# SF32LB52x register map
File version: 1.0
CPU: CM33 r0p1, little endian, MPU, FPU, 3 interrupt priority bits
Registers are 32-bit, read-write, reset 0x0 unless marked. A register's access mark holds for its fields unless they carry their own. Offsets are from the block's base; [hi:lo] are bit positions; {n}, {i} and the like mark numbered series.

## HPSYS_AON
Base 0x500C0000
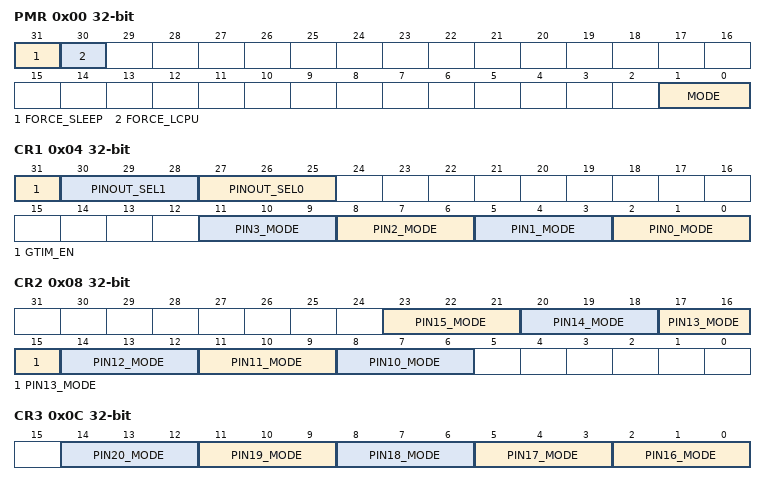
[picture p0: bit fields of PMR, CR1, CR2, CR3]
0x00 PMR — Power Mode Register
  [31] FORCE_SLEEP — Set 1 to force enter low power mode. Will be cleared automatically
  [30] FORCE_LCPU — for debug only
  [1:0] MODE — Power Mode: 2'h0 - active; 2'h1 - light sleep; 2'h2 - deep sleep; 2'h3 - standby
0x04 CR1 — Control Register 1
  [31] GTIM_EN — Enable global timer
  [30:28] PINOUT_SEL1 — for debug only
  [27:25] PINOUT_SEL0 — for debug only
  [11:9] PIN3_MODE — mode for wakeup PIN3 (PA27)
  [8:6] PIN2_MODE — mode for wakeup PIN2 (PA26)
  [5:3] PIN1_MODE — mode for wakeup PIN1 (PA25)
  [2:0] PIN0_MODE — mode for wakeup PIN0 (PA24) 0 - high level, 1 - low level, 2 - pos edge, 3 - neg edge, 4/5/6/7: pos or neg edge
0x08 CR2 — Control Register 2
  [3n-22:3n-24] PIN{n}_MODE (n=11..15) — mode for wakeup PIN{n} (PA{n+24})
  [8:6] PIN10_MODE — mode for wakeup PIN10 (PA34) 0 - high level, 1 - low level, 2 - pos edge, 3 - neg edge, 4/5/6/7: pos or neg edge
0x0C CR3 — Control Register 3
  [3n-46:3n-48] PIN{n}_MODE (n=17..20) — mode for wakeup PIN{n} (PA{n+24})
  [2:0] PIN16_MODE — mode for wakeup PIN16 (PA40) 0 - high level, 1 - low level, 2 - pos edge, 3 - neg edge, 4/5/6/7: pos or neg edge
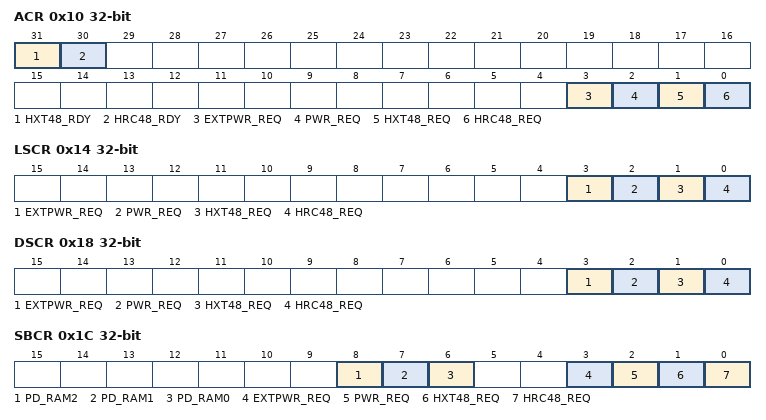
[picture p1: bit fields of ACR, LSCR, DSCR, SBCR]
0x10 ACR — Active Mode Control register
  [31] HXT48_RDY — Indicate hxt48 is ready
  [30] HRC48_RDY — Indicate hrc48 is ready
  [3] EXTPWR_REQ — for debug only
  [2] PWR_REQ — Request power during Active mode
  [1] HXT48_REQ — Request hxt48 in active mode
  [0] HRC48_REQ — Request hrc48 in active mode
0x14 LSCR — Light Sleep Ctrl Register
  [3] EXTPWR_REQ — for debug only
  [2] PWR_REQ — Request power during Light Sleep mode
  [1] HXT48_REQ — Request hxt48 in Light Sleep mode
  [0] HRC48_REQ — Request hrc48 in Light Sleep mode
0x18 DSCR — Deep Sleep Ctrl Register
  [3] EXTPWR_REQ — for debug only
  [2] PWR_REQ — Request power during Deep Sleep mode
  [1] HXT48_REQ — Request hxt48 in Deep Sleep mode
  [0] HRC48_REQ — Request hrc48 in Deep Sleep mode
0x1C SBCR — Standby Mode Ctrl Register
  [8] PD_RAM2 — for debug only
  [7] PD_RAM1 — for debug only
  [6] PD_RAM0 — for debug only
  [3] EXTPWR_REQ — for debug only
  [2] PWR_REQ — Request power during Standby mode
  [1] HXT48_REQ — Request hxt48 in Standby mode
  [0] HRC48_REQ — Request hrc48 in Standby mode
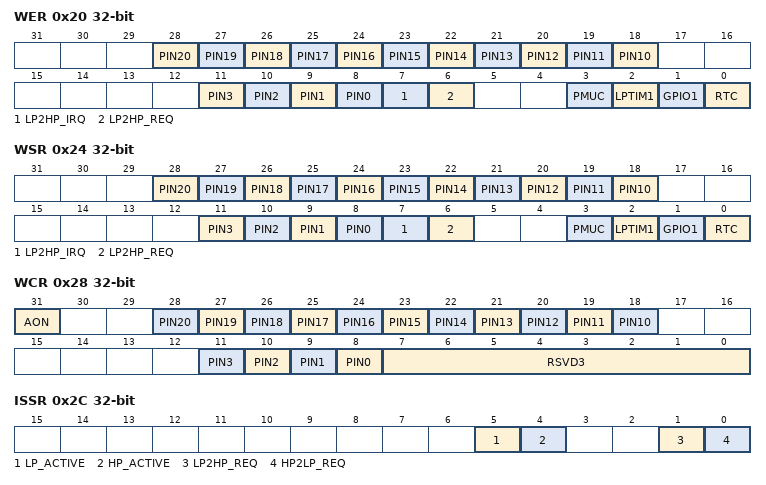
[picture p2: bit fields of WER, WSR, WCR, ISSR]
0x20 WER — Wakeup Enable register
  [n+8] PIN{n} (n=10..20) — Set 1 to enable PA{n+24} as wakeup source
  [n+8] PIN{n} (n=0..3) — Set 1 to enable PA{n+24} as wakeup source
  [7] LP2HP_IRQ — Set 1 to enable MAILBOX2 as wakeup source
  [6] LP2HP_REQ — Set 1 to enable LPSYS request as wakeup source
  [3] PMUC — Set 1 to enable PMUC as wakeup source
  [2] LPTIM1 — Set 1 to enable LPTIM1 as wakeup source
  [1] GPIO1 — Set 1 to enable IO(PA) as wakeup source
  [0] RTC — Set 1 to enable RTC as wakeup source
0x24 WSR — Wakeup Status register
  [n+8] PIN{n} (n=10..20) — Indicates the wakeup status from PA{n+24} request. Note: the status is masked by WER
  [n+8] PIN{n} (n=0..3) — Indicates the wakeup status from PA{n+24} request. Note: the status is masked by WER
  [7] LP2HP_IRQ — Indicates the wakeup status from MAILBOX2. Note: the status is masked by WER
  [6] LP2HP_REQ — Indicates the wakeup status from LPSYS request. Note: the status is masked by WER
  [3] PMUC — Indicates the wakeup status from PMUC. Note: the status is masked by WER
  [2] LPTIM1 — Indicates the wakeup status from LPTIM1. Note: the status is masked by WER
  [1] GPIO1 — Indicates the wakeup status from IO(PA). Note: the status is masked by WER
  [0] RTC — Indicates the wakeup status from RTC. Note: the status is masked by WER
0x28 WCR — Wakeup Clear register
  [31] AON — Write 1 to clear the AON wakeup IRQ status
  [n+8] PIN{n} (n=10..20) — Write 1 to clear PA{n+24} wakeup source. Only valid if PIN wakeup is configured as edge trigger
  [n+8] PIN{n} (n=0..3) — Write 1 to clear PA{n+24} wakeup source. Only valid if PIN wakeup is configured as edge trigger
  [7:0] RSVD3 — Note: for RTC/IO(PA)/LPTIM/PMUC, clear the wakeup status directly in the orignal module
0x2C ISSR — Inter System Wakeup Register
  [5] LP_ACTIVE — Read 1 indicates LPSYS is active
  [4] HP_ACTIVE — Write 1 to indicates HPSYS is active
  [1] LP2HP_REQ — Indicate LPSYS request exists
  [0] HP2LP_REQ — Write 1 to request LPSYS to stay in active mode
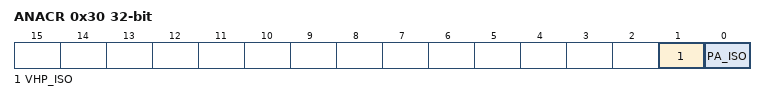
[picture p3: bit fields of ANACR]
0x30 ANACR — Analog Control Register
  [1] VHP_ISO — Set 1 to force off all HPSYS related analog modules
  [0] PA_ISO — Set 1 to force IO(PA) into retention mode
0x34 GTIMR — Global Timer Register
  [31:0] CNT — Global timer value
0x38 RESERVE0 — Reserved Register 0
  [31:0] DATA — for debug only
0x3C RESERVE1 — Reserved Register 1
  [31:0] DATA — for debug only
